# dbb_rx register map
Registers are 16-bit, access not given, no defined reset value unless marked. A register's access mark holds for its fields unless they carry their own. Offsets are from the block's base; lines under a group give offsets from that group; [hi:lo] are bit positions; {n}, {i} and the like mark numbered series; 'fields as' and 'values as' point back to an identical list; <NAME> marks a mode.

## Memory map
? dbb_rx — PAN2G RX Config

## dbb_rx — PAN2G RX Config
Base ?
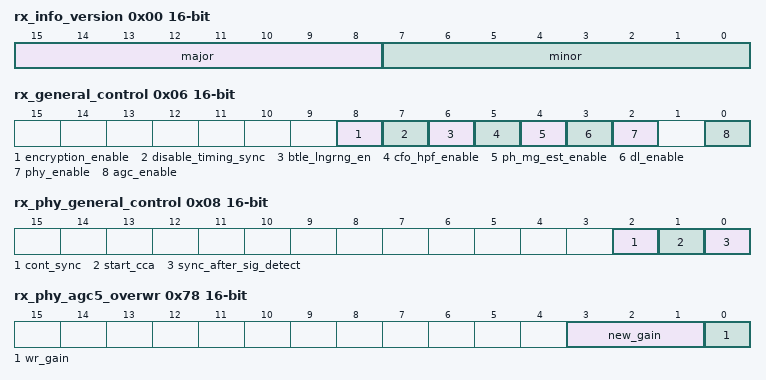
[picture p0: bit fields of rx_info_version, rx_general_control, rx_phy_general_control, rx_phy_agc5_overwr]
0x00 rx_info_version — version
  [15:8] major — Version major part
  [7:0] minor — Version minor part
0x04 rx_general_standard — Standard: 1 = Zigbee (15.4), 2 = BAN (15.6), 3 = Bluetooth Low Energy (BTLE)
  [1:0] standard — Wireless standard to use.
    1=Zigbee (15.4); 2=ban (BAN (15.6).); 3=BTLE (Bluetooth Low Energy (BTLE).)
0x06 rx_general_control — control
  [8] encryption_enable — enables encryption
  [7] disable_timing_sync — If high then the timingsync algorithem is disabled
  [6] btle_lngrng_en — If the PHY is configuted for BTLE use this bit to setup the phy in BTLE long range mode
  [5] cfo_hpf_enable — Enable CFO high pass filter (only works when phase magnitude estimator is enabled)
  [4] ph_mg_est_enable — Enable phase magnitude estimator
  [3] dl_enable — Enable BB datalink
  [2] phy_enable — Enable BB PHY layer
  [0] agc_enable — Enable automatic gain control
0x08 rx_phy_general_control — control
  [2] cont_sync — Continuous timing synchronization: 0 = Timing synchronization till PLD , 1 = Continuous timing synchronization during PLD
    0=until_pld (Timing synchronization till PLD.); 1=during_pld (Continuous timing synchronization during PLD.)
  [1] start_cca — Start clear channel assessment
  [0] sync_after_sig_detect — Start timing sync and frame sync after signal is detected
0x0A rx_phy_general_agc_freeze_timer — Set the amount of PHY clockcycles after signal detect after which the AGC gain control will be frozen
0x0C rx_phy_general_sig_detect_init_timer — After activating the RX phy the agc and frondend are allowed sig_detect_init_timer clock ticks to settle at the initial gain of the AGC befor the signal detect logic is activated. This is required to prevent false signal detection. This feature is disabled if this register is set to 0
0x0E rx_phy_general_sig_detect_rst_timer — After the AGC has switched without a signal detect beiing high then after sig_detect_rst_timer clock ticks and still nog signal detect the signal detect logic is reset. This allows the signal detect logic to "learn" the new noise level of the new gain and prevent false triggering. This feature is disabled if this register is set to 0
0x10 rx_phy_general_ddc_rst_timer — Reset the DDC filter is there is no signal detect within the set amount of clk cycles to prevent leaning the wrong DC offset level due to interference; when set to 0 no rst is generated
{0x14+2i} rx_phy_ddc_alpha_start[{i}] (i=0..7) — Dynamic DC offset compensation alpha start values (one value for each gain step)
{0x24+2i} rx_phy_ddc_alpha_stop[{i}] (i=0..7) — Dynamic DC offset compensation alpha stop values (one value for each gain step)
{0x34+2i} rx_phy_ddc_alpha_step[{i}] (i=0..7) — Dynamic DC offset compensation alpha step values (one value for each gain step)
{0x44+2i} rx_phy_ddc_beta[{i}] (i=0..7) — Dynamic DC offset compensation Beta values (one value for each gain step)
0x54 rx_phy_ddc_rst_tmr — Setpoint for the filter reset delay; After the agc_enc is ready with writting new AFE settings wait i_cgf_rst_tmr clk cycles and reset the DDC filter
{0x56+2i} rx_phy_ddc_offs_i[{i}] (i=0..7) — Signed value that will be added to the I channel befor the DC offset filter to allow manual correction of the DC offset, one value per AGC gain step
{0x66+2i} rx_phy_ddc_offs_q[{i}] (i=0..7) — Signed value that will be added to the Q channel befor the DC offset filter to allow manual correction of the DC offset, one value per AGC gain step
0x78 rx_phy_agc5_overwr — overwr
  [3:1] new_gain — Gain level used when gain is fixed
  [0] wr_gain — Change gain to fixed value
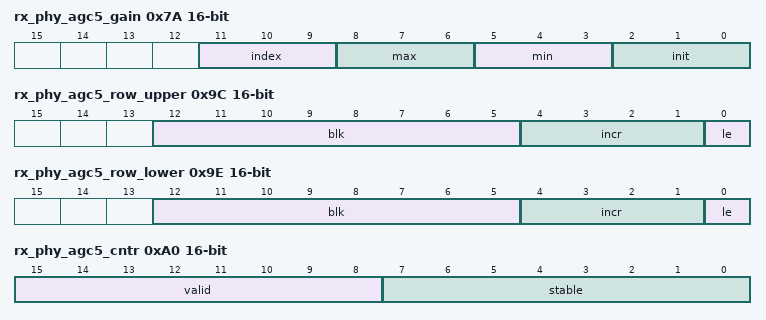
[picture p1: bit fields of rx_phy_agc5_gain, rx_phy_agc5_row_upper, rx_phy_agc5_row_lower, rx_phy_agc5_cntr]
0x7A rx_phy_agc5_gain — gain
  [11:9] index — Gain index readout for debug purposes
  [8:6] max — Maximum gain index
  [5:3] min — Minimum gain index
  [2:0] init — Gain index used at beginning of procedure
0x7C rx_phy_agc5_thresh7upper — Gain is increased/decreased when samples are above/below this threshold
0x7E rx_phy_agc5_thresh7lower — Gain is increased/decreased when samples are above/below this threshold
0x80 rx_phy_agc5_thresh6upper — Gain is increased/decreased when samples are above/below this threshold
0x82 rx_phy_agc5_thresh6lower — Gain is increased/decreased when samples are above/below this threshold
0x84 rx_phy_agc5_thresh5upper — Gain is increased/decreased when samples are above/below this threshold
0x86 rx_phy_agc5_thresh5lower — Gain is increased/decreased when samples are above/below this threshold
0x88 rx_phy_agc5_thresh4upper — Gain is increased/decreased when samples are above/below this threshold
0x8A rx_phy_agc5_thresh4lower — Gain is increased/decreased when samples are above/below this threshold
0x8C rx_phy_agc5_thresh3upper — Gain is increased/decreased when samples are above/below this threshold
0x8E rx_phy_agc5_thresh3lower — Gain is increased/decreased when samples are above/below this threshold
0x90 rx_phy_agc5_thresh2upper — Gain is increased/decreased when samples are above/below this threshold
0x92 rx_phy_agc5_thresh2lower — Gain is increased/decreased when samples are above/below this threshold
0x94 rx_phy_agc5_thresh1upper — Gain is increased/decreased when samples are above/below this threshold
0x96 rx_phy_agc5_thresh1lower — Gain is increased/decreased when samples are above/below this threshold
0x98 rx_phy_agc5_thresh0upper — Gain is increased/decreased when samples are above/below this threshold
0x9A rx_phy_agc5_thresh0lower — Gain is increased/decreased when samples are above/below this threshold
0x9C rx_phy_agc5_row_upper — row_upper
  [12:5] blk — Specifies the number of blocks the threshold has to be reached before the gain is changed.
  [4:1] incr — specifies the increment value (signed - can be used to increase and decrease)
  [0] le — specifies if gain is incremented when samples are larger-or-equal to this threshold (smaller otherwise)
0x9E rx_phy_agc5_row_lower — row_lower
  fields as rx_phy_agc5_row_upper
0xA0 rx_phy_agc5_cntr — cntr
  [15:8] valid — Number of samples needed after a gain change before samples are considered valid
  [7:0] stable — Number of samples in a block and also number valid samples before gain is considered stable
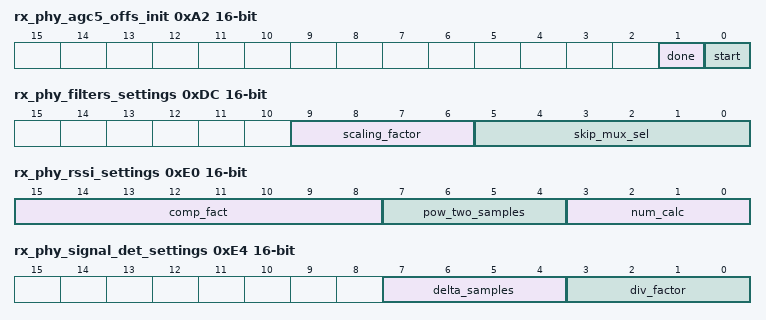
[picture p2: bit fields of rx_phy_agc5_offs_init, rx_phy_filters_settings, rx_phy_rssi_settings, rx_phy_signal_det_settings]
0xA2 rx_phy_agc5_offs_init — offs_init
  [1] done — Offset table has been initialized.
  [0] start — Initialize offset table
{0xA4+2i} rx_phy_phsmagest_filter_coeff[{i}] (i=0..9) — Filter to open the phase magniture output eye *signed*.
0xB8 rx_phy_phsmagest_scaling_factor — Scalingfactor for the eye opening filter
{0xBC+2i} rx_phy_filters_coefficients[{i}] (i=0..15) — Filter coefficients *signed*.
0xDC rx_phy_filters_settings — settings
  [9:6] scaling_factor — Number of bits that filter output must be shifted right
  [5:0] skip_mux_sel — Filter length selection. When bit x is 1, data is input after 3x taps, effectively bypassing them.
0xE0 rx_phy_rssi_settings — settings
  [15:8] comp_fact — Compansation factor in dB to compensate for: receiver sensitivity, filter gain, etc. (two's complement format)
  [7:4] pow_two_samples — Number of samples to average over per RSSI calculation is equal to 2^"pow_two_samples"
  [3:0] num_calc — Number of consecutive RSSI calculations
0xE2 rx_phy_rssi_ed_threshold — Energy detection threshold in dBm; must be compensated when multiple consecutive RSSI calculations are done. (two's complement format)
0xE4 rx_phy_signal_det_settings — settings
  [7:4] delta_samples — Number samples difference to calculate rise of avg after filter with
  [3:0] div_factor — Threshold that the average signal power needs to cross, before a signal is detected
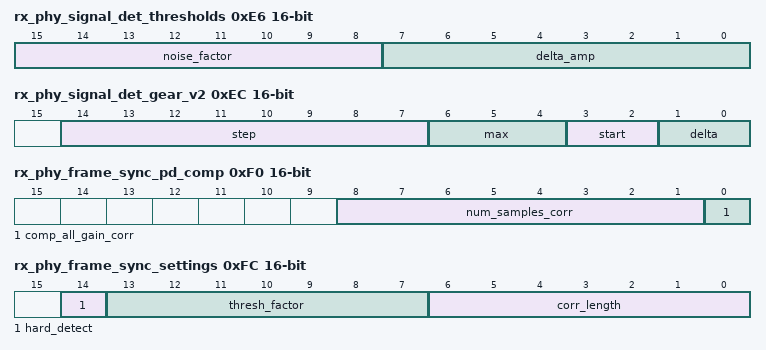
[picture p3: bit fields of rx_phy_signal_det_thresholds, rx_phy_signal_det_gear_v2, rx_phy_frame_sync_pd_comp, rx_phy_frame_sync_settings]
0xE6 rx_phy_signal_det_thresholds — thresholds
  [15:8] noise_factor — Threshold factor for scaling the threshold up
  [7:0] delta_amp — Threshold for difference in "i_delta_samples" number of samples
0xE8 rx_phy_signal_det_select_v2 — Signal detector block selection (0=old V1 implementation, 1=new V2 implementation)
0xEA rx_phy_signal_det_settings_v2_div_factor — settings_v2
  [3:0] div_factor — Threshold that the average signal power needs to cross, before a signal is detected
0xEC rx_phy_signal_det_gear_v2 — gear_v2
  [14:7] step — Slow IIR gear update step (input samples)
  [6:4] max — Slow IIR final gear value
  [3:2] start — Slow IIR initial gear value (-2 ~ 0)
  [1:0] delta — Slow IIR gear increment
0xEE rx_phy_signal_det_thresholds_v2_noise_factor — thresholds_v2
  [4:0] noise_factor — Threshold factor for scaling the threshold up (2 integer and 3 fractional bits)
0xF0 rx_phy_frame_sync_pd_comp — pd_comp
  [8:1] num_samples_corr — Number of samples set to zero after AGC gain correction
  [0] comp_all_gain_corr — Compensate for all gain corrections: 1 = Compensate all, 0 = Only compensate for first correction
    1=all (Compensate all.); 0=first (Only compensate for first correction.)
{0xF4+2i} rx_phy_frame_sync_sfd[{i}] (i=0..3) — Start of frame delimiter (last 64 bits of preamble + sfd sequence).
0xFC rx_phy_frame_sync_settings — settings
  [14] hard_detect — Detection mode: 1 = bit based hard detection, 0 = phase sample based soft detection
    1=all (bit based hard detection.); 0=sample (phase sample based soft detection.)
  [13:7] thresh_factor — Multiplication factor which determines the synchronization threshold (Must be smaller then "corr_length").
  [6:0] corr_length — Number if LSBs in "sfd" used for correlation.
0xFE rx_phy_frame_sync_settings_min_corr_val — Minimal correlation value before a start of frame is detected. It can be used as an extra measure against false start of frame detections.
0x100 rx_phy_frame_sync_timeout_tmr_periode — Start of frame detection timeout timer period. Setting this periode to zero disables the timer. The timer runs on the RX clock frequency.
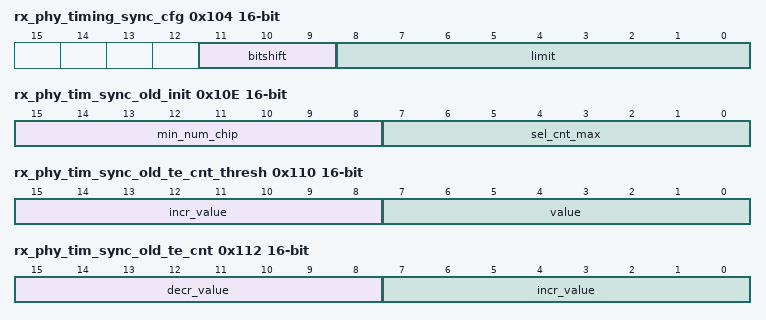
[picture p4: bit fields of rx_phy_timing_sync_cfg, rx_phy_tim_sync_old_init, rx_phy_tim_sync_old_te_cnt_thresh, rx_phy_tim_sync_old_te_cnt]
0x104 rx_phy_timing_sync_cfg — cfg
  [11:9] bitshift — The amount of bitshifts that are done after the accumulator (default /64)
  [8:0] limit — All input values above this set threshold are treaded as non-valid input samples by the module
0x106 rx_phy_timing_sync_log_sum — Log the current value of the acculator logic for debugging / monitoring
0x108 rx_phy_tim_sync_old_cfg — Timing sync general config: 0 = Dynamic thresholding mode, 1 = Static thresholding mode
  [0] cfg — All input values above this set threshold are treaded as non-valid input samples by the module
    1=Static thresholding mode; 0=Dynamic thresholding mode
0x10A rx_phy_tim_sync_old_te_thresh — Timing error static threshold value (for static thresholding mode)
0x10C rx_phy_tim_sync_old_te_thresh_scaling — Timing error dynamic threshold scaling config (for dynamic thresholding mode)
0x10E rx_phy_tim_sync_old_init — init
  [15:8] min_num_chip — Minimum number of symbols before starting adjustments (after TS is enabled)
  [7:0] sel_cnt_max — Maximum value of sample select counter
0x110 rx_phy_tim_sync_old_te_cnt_thresh — te_cnt_thresh
  [15:8] incr_value — Timing error counter threshold increase value (after each adjustment)
  [7:0] value — Timing error counter threshold value
0x112 rx_phy_tim_sync_old_te_cnt — te_cnt
  [15:8] decr_value — Timing error counter decrease value (when no timing error detected for current symbol)
  [7:0] incr_value — Timing error counter increase value (when timing error detected for current symbol)
0x114 rx_phy_tim_sync_old_te_fifo_max_ptr — Number of timing error events to be averaged
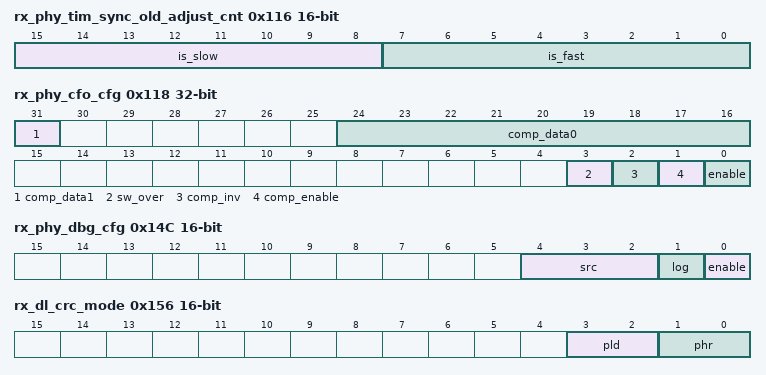
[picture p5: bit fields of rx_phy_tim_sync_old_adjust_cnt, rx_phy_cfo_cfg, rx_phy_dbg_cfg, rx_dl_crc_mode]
0x116 rx_phy_tim_sync_old_adjust_cnt — adjust_cnt
  [15:8] is_slow — Number of adjustments due to late sampling (read-only status register)
  [7:0] is_fast — Number of adjustments due to early sampling (read-only status register)
0x118 rx_phy_cfo_cfg 32-bit — CFO estimation and compensation config general (cfg(0)=enable, cfg(1)=comp. enable, cfg(2)=comp. data sign invert, cfg(3)=comp. data SW override enable, cfg(31) and cfg(24:16)=CFO comp. data used in override mode)
  [31] comp_data1 — cfg(31) and cfg(24:16)=CFO comp. data used in override mode).
  [24:16] comp_data0 — cfg(31) and cfg(24:16)=CFO comp. data used in override mode).
  [3] sw_over — comp. data SW override enable.
  [2] comp_inv — comp data sign invert.
  [1] comp_enable
  [0] enable
{0x11C+2i} rx_phy_cfo_filter_coefficients[{i}] (i=0..8) — CFO comp. filter coefficients
0x12E rx_phy_cfo_filter_scaling — CFO comp. filter scaling
0x130 rx_phy_cfo_pa_precnt_num — CFO comp. delay between internal energy detection and start of CFO measurement
0x132 rx_phy_cfo_ph_accum_part_num — CFO comp. number of samples to accumulate for partial CFO estimate
0x134 rx_phy_cfo_ed_thresh_factor — CFO comp. energy detection threshold
0x136 rx_phy_cfo_ed_slow_factor — CFO comp. slow energy estimate scaling factor
0x138 rx_phy_cfo_ed_fast_factor — CFO comp. fast energy estimate scaling factor
0x13C rx_phy_cfo_pa_max_limit_val — CFO comp. maximum phase accumulation value limit
0x140 rx_phy_cfo_cfo_est — CFO comp. CFO estimation result (scaled)
0x144 rx_phy_cfo_cfo_est_khz — CFO comp. CFO estimation result (kHz)
0x148 rx_debug_dl_lb — loop back datalink: 0 = normal mode, 1 = loopback mode
  [0] loop — loop back datalink
    1=loopback mode; 0=normal mode
0x14C rx_phy_dbg_cfg — RX debug config (cfg(0)=enable, cfg(1)=log to mem enable, cfg(4:2)=data source (0=IQ (after AGC), 1=IQ (after filter), 2=IQ (before AGC), 3=phase diff, 4=dbg counter))
  [4:2] src — data source.
    0=iq_after_agc; 1=iq_after_filter; 2=iq_before_agc; 3=phase diff; 4=dbg_counter
  [1] log — log to mem enable.
  [0] enable
0x150 rx_phy_dbg_data — RX debug IQ data register
0x154 rx_dl_bypass — Bypass the datalink layer. When this bit is set the payload data is sent directly to the payload memory
0x156 rx_dl_crc_mode — crc_mode
  [3:2] pld — Payload CRC type: 0 = data bypassed, 1 = CRC-4, 2= CRC-16, 3 = CRC-24
    0=byp (data bypassed.); 1=crc4; 2=crc16; 3=crc24
  [1:0] phr — Header CRC type: 0 = data bypassed, 1 = CRC-4, 2 = CRC-16, 3 = CRC-24
    0=byp (data bypassed.); 1=crc4; 2=crc16; 3=crc24
0x158 rx_dl_crc_init_phr — CRC LFSR initialization value for the header
0x15C rx_dl_crc_init_pld — CRC LFSR initialization value for the payload
0x160 rx_dl_crc_residu — The CRC residue value
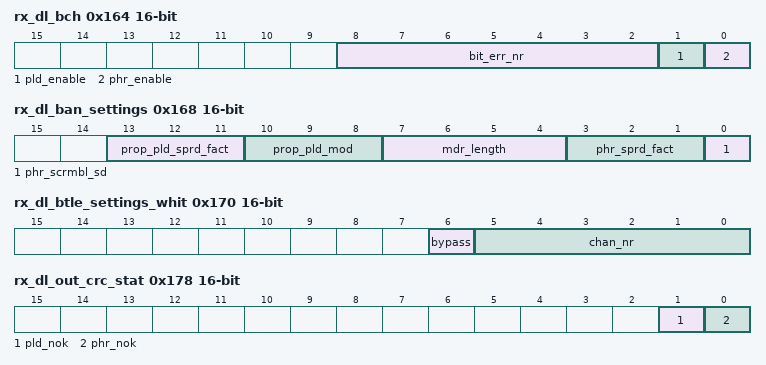
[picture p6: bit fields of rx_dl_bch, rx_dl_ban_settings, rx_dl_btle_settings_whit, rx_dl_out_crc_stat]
0x164 rx_dl_bch — bch
  [8:2] bit_err_nr — BCH errors counter (bit error counter per frame)
  [1] pld_enable — BCH decoding enabled on the payload
  [0] phr_enable — BCH decoding enabled on the header
0x166 rx_dl_sprd_seq_err_nr — sprd
  [11:0] seq_err_nr — Despreader errors counter (sequence error counter per frame)
0x168 rx_dl_ban_settings — ban_settings
  [13:11] prop_pld_sprd_fact — Proprietary mode payload spread factor: 1 = sprd_fact_1, 2 = sprd_fact_2, 3 = sprd_fact_4, 4 = sprd_fact_8, 5 = sprd_fact_16
    1=sprd_fact_1; 2=sprd_fact_2; 3=sprd_fact_4; 4=sprd_fact_8; 5=sprd_fact_16
  [10:8] prop_pld_mod — Proprietary mode payload modulation: OQPSK=0, 1 = DBPSK 2 = DQPSK, 3 = D8PSK, 4 = GMSK, 5 = GFSK
    0=OQPSK; 1=DBPSK; 2=DQPSK; 3=D8PSK; 4=GMSK; 5=GFSK
  [7:4] mdr_length — MAC header length in bytes
  [3:1] phr_sprd_fact — Header spread factor: 1 = sprd_fact_1, 2 = sprd_fact_2, 3 = sprd_fact_4, 4 = sprd_fact_8, 5 = sprd_fact_16
    values as prop_pld_sprd_fact
  [0] phr_scrmbl_sd — Header scrambler seed, used to initialize the LFSR of the scrambler module when processing the header
0x16C rx_dl_btle_settings_adv_acc_addr — Advertisement channel access address used to determine if frame is for advertisement channel
0x170 rx_dl_btle_settings_whit — btle_settings_whit
  [6] bypass — Whitening bypass enable
  [5:0] chan_nr — Channel number used dewhitening
0x172 rx_dl_phr_modulation — Header modulation: OQPSK=0, 1 = DBPSK 2 = DQPSK, 3 = D8PSK, 4 = GMSK, 5 = GFSK
  [2:0] mod — Header modulation.
    0=OQPSK; 1=DBPSK; 2=DQPSK; 3=D8PSK; 4=GMSK; 5=GFSK
0x174 rx_phy_rssi_out_pwr — Power calculated by the RSSI module in dBm. (two's complement format)
0x178 rx_dl_out_crc_stat — crc_stat
  [1] pld_nok — PLD CRC status bit: 0 = CRC is okay, 1 = CRC is not okay
  [0] phr_nok — PHR CRC status bit: 0 = CRC is okay, 1 = CRC is not okay
0x17A rx_dl_out_phr — Header containing standard dependant information
0x17C rx_dl_out_acc_add_nok — Is high when in coded phy mode the received access adress is not matching with the expected address and via this way the rx is terminated
0x17E rx_dl_out_ci — When receiving a BTLE coded phy packet this field will indicate the value of the CI field (00 = S8 mode, 01=S2 mode, others resevered for future use)
  [0] ci — ci field of packet.
    0=S8; 1=S2
{0x180+4i} rx_pld_mem[{i}] (i=0..65) — Payload memory: 66 address
0x288 rx_phy_signal_det2_timeout_tmr_periode — Signal detect timeout timer which goes off when no SFD is detected. Setting this periode to zero disables the timer. The timer runs on the RX clock frequency.
0x28C rx_phy_signal_det2_ed_slow_fact — Energy detection slow factor
0x28E rx_phy_signal_det2_ed_fast_fact — Energy detection fast factor
0x290 rx_phy_signal_det2_ed_threshold_fact — Energy detection threshold factor
0x294 rx_phy_signal_det2_ed_timeout_tmr_periode — Energy detection timeout timer periode
0x298 rx_phy_signal_det2_stop_high_filt_corner — Number of samples it takes to go from alpha/beta/gamma 2 to alpha/beta/gamma 3
0x29A rx_phy_signal_det2_beta_mux_en_stage — Filter multiplexer enable stage (0 = multiplexer and beta filter disabled), 1 = alpha 1, 2 = alpha 2, 3 = alpha 3, 4 = alpha 4)
0x29C rx_phy_signal_det2_beta_mux_threshold 32-bit — Beta filter select threshold
0x2A0 rx_phy_signal_det2_gamma_mux_en_stage — Filter multiplexer enable stage (0 = multiplexer and gamma filter disabled), 1 = alpha 1, 2 = alpha 2, 3 = alpha 3, 4 = alpha 4)
0x2A4 rx_phy_signal_det2_gamma_mux_threshold — Gamma filter select threshold
{0x2A8+2i} rx_phy_signal_det2_alpha[{i}] (i=0..3) — Filter multiplication factor for alpha filter
{0x2B0+2i} rx_phy_signal_det2_beta[{i}] (i=0..3) — Filter multiplication factor for beta filter
{0x2B8+2i} rx_phy_signal_det2_gamma[{i}] (i=0..3) — Filter multiplication factor for gamma filter
0x2C0 rx_phy_cfo2_ed_timeout_tmr_periode — Coarse CFO energy detection timeout timer periode
0x2C4 rx_phy_cfo2_cfg_ph_accum_upscl_fact — Coarse CFO phase accumulation upscaling multiplication factor
0x2C6 rx_phy_cfo2_cfg_ph_accum_dwnscl_fact — Coarse CFO phase accumulation downscaling division factor (downscaling is done by 2^cfg_ph_accum_dwnscl_fact)
0x2C8 rx_phy_cfo2_cfg_ph_accum_comp — Coarse CFO phase accumulation compensation for compensating default phase information
0x2CC rx_phy_btlespeed_anti_alias_enable — Anti-alias filter enable for BTLE high-speed mode
{0x2CE+2i} rx_phy_btlespeed_filter_coeff[{i}] (i=0..3) — Anti-alias filter coefficients (7-TAPs)
0x2D6 rx_phy_btlespeed_scaling_factor — Anti-alias filter scalingfactor
0x2D8 rx_phy_frame_sync_lr_corr_length — Number if LSBs in "sfd" used for correlation when in coded phy mode
0x2DA rx_phy_frame_sync_lr_thresh_factor — Multiplication factor which determines the synchronization threshold (Must be smaller then "corr_length") when in coded phy mode
